# STM32U535 register map
File version: 1.7
CPU: CM33 r0p1, little endian, MPU, FPU, 4 interrupt priority bits
Registers are 32-bit, read-write, reset 0x0 unless marked. A register's access mark holds for its fields unless they carry their own. Offsets are from the block's base; [hi:lo] are bit positions; lines under a group give offsets from that group; {n}, {i} and the like mark numbered series; 'fields as' and 'values as' point back to an identical list.

## TAMP — Tamper and backup registers
Base 0x46007C00
Same registers: SEC_TAMP 0x56007C00
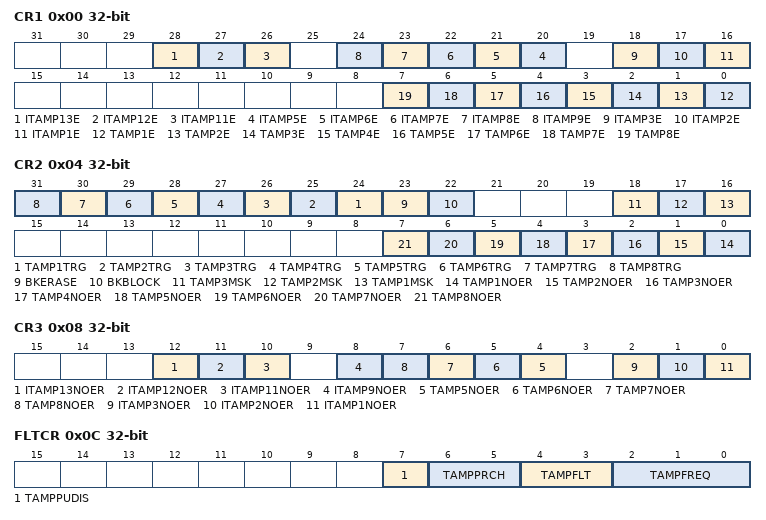
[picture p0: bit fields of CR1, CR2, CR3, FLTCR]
0x00 CR1 — control register 1
  [28] ITAMP13E
  [27] ITAMP12E
  [26] ITAMP11E — TAMP1E
  [n+15] ITAMP{n}E (n=5..9)
  [18] ITAMP3E
  [17] ITAMP2E
  [16] ITAMP1E
  [n-1] TAMP{n}E (n=1..8)
0x04 CR2 — control register 2
  [n+23] TAMP{n}TRG (n=1..8), [23] BKERASE, [22] BKBLOCK, [18] TAMP3MSK, [17] TAMP2MSK, [16] TAMP1MSK, [n-1] TAMP{n}NOER (n=1..8)
0x08 CR3 — control register 3
  [12] ITAMP13NOER, [11] ITAMP12NOER, [10] ITAMP11NOER, [8] ITAMP9NOER, [n-1] TAMP{n}NOER (n=5..8), [2] ITAMP3NOER, [1] ITAMP2NOER, [0] ITAMP1NOER
0x0C FLTCR — TAMP filter control register
  [7] TAMPPUDIS, [6:5] TAMPPRCH, [4:3] TAMPFLT, [2:0] TAMPFREQ
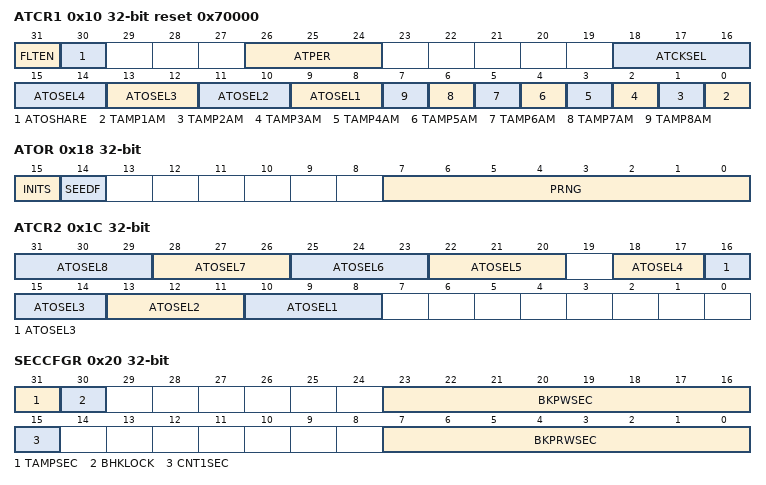
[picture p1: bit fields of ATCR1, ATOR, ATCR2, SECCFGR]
0x10 ATCR1 reset 0x70000 — TAMP active tamper control register
  [31] FLTEN — ATOSHARE
  [30] ATOSHARE
  [26:24] ATPER
  [18:16] ATCKSEL
  [2n+7:2n+6] ATOSEL{n} (n=1..4)
  [n-1] TAMP{n}AM (n=1..8)
0x14 ATSEEDR — TAMP active tamper seed register
  [31:0] SEED
0x18 ATOR ro — TAMP active tamper output register
  [15] INITS, [14] SEEDF, [7:0] PRNG
0x1C ATCR2 — TAMP active tamper control register 2
  [3n+7:3n+5] ATOSEL{n} (n=5..8), [18:17] ATOSEL4, [16:14] ATOSEL3, [13:11] ATOSEL2, [10:8] ATOSEL1
0x20 SECCFGR — TAMP secure mode register
  [31] TAMPSEC, [30] BHKLOCK, [23:16] BKPWSEC, [15] CNT1SEC, [7:0] BKPRWSEC
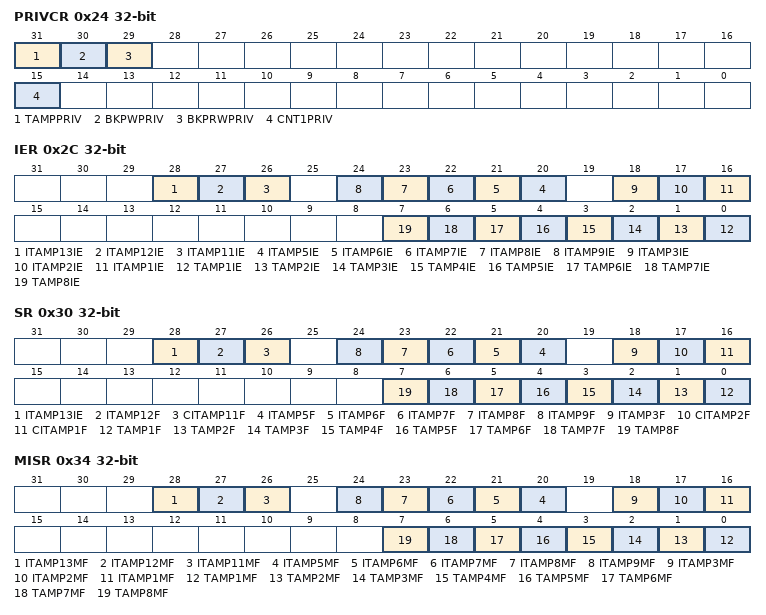
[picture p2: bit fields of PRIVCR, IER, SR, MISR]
0x24 PRIVCR — TAMP privilege mode control register
  [31] TAMPPRIV, [30] BKPWPRIV, [29] BKPRWPRIV, [15] CNT1PRIV
0x2C IER — TAMP interrupt enable register
  [28] ITAMP13IE, [27] ITAMP12IE, [26] ITAMP11IE, [n+15] ITAMP{n}IE (n=5..9), [18] ITAMP3IE, [17] ITAMP2IE, [16] ITAMP1IE, [n-1] TAMP{n}IE (n=1..8)
0x30 SR ro — TAMP status register
  [28] ITAMP13IE, [27] ITAMP12F, [26] CITAMP11F, [n+15] ITAMP{n}F (n=5..9), [18] ITAMP3F, [17] CITAMP2F, [16] CITAMP1F, [n-1] TAMP{n}F (n=1..8)
0x34 MISR ro — TAMP masked interrupt status register
  [28] ITAMP13MF, [27] ITAMP12MF, [26] ITAMP11MF, [n+15] ITAMP{n}MF (n=5..9), [18] ITAMP3MF, [17] ITAMP2MF, [16] ITAMP1MF, [n-1] TAMP{n}MF (n=1..8)
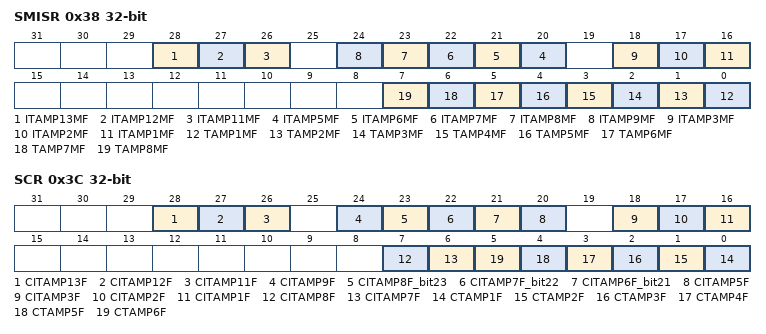
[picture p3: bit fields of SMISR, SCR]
0x38 SMISR ro — TAMP secure masked interrupt status register
  fields as MISR
0x3C SCR — TAMP status clear register
  [28] CITAMP13F
  [27] CITAMP12F
  [26] CITAMP11F
  [24] CITAMP9F
  [23] CITAMP8F_bit23
  [22] CITAMP7F_bit22
  [21] CITAMP6F_bit21
  [20] CITAMP5F
  [18] CITAMP3F
  [17] CITAMP2F
  [16] CITAMP1F
  [7] CITAMP8F — CITAMP3F
  [6] CITAMP7F — CITAMP3F
  [n-1] CTAMP{n}F (n=1..6)
0x40 COUNT1R ro — TAMP monotonic counter 1register
  [31:0] COUNT
0x54 ERCFGR — TAMP erase configuration register
  [0] ERCFG0
{0x100+4i} BKP{i}R (i=0..31) — TAMP backup register
  [31:0] BKP

## TIM6 — General-purpose-timers
Base 0x40001000
Same registers: TIM7 0x40001400, SEC_TIM6 0x50001000, SEC_TIM7 0x50001400
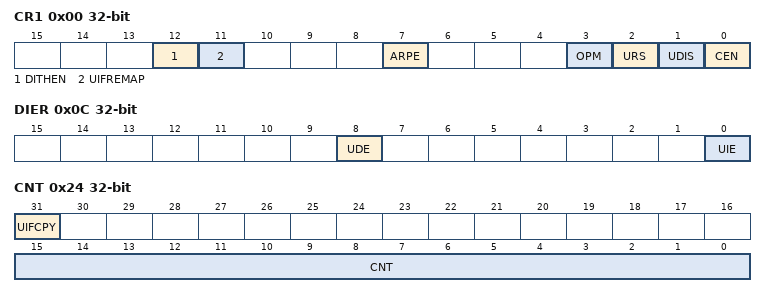
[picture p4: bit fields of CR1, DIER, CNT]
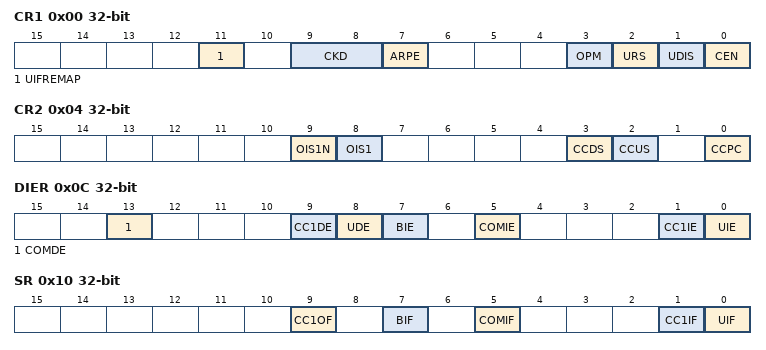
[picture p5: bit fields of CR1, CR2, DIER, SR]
0x00 CR1 — control register 1
  [12] DITHEN — Dithering Enable
  [11] UIFREMAP — UIF status bit remapping
  [7] ARPE — Auto-reload preload enable
  [3] OPM — One-pulse mode
  [2] URS — Update request source
  [1] UDIS — Update disable
  [0] CEN — Counter enable
0x04 CR2 — control register 2
  [6:4] MMS — Master mode selection
0x0C DIER — DMA/Interrupt enable register
  [8] UDE, [0] UIE
0x10 SR — status register
  [0] UIF
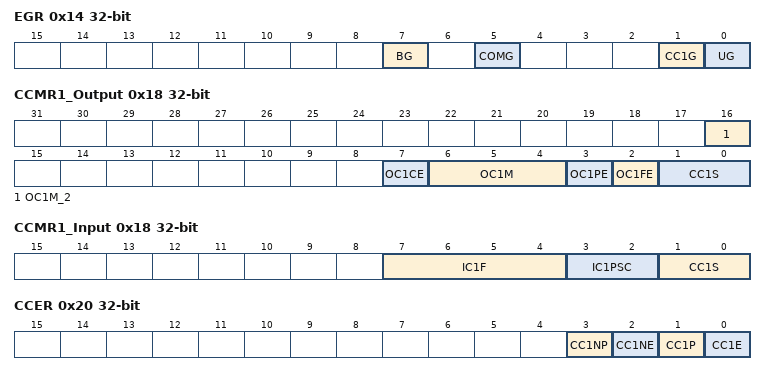
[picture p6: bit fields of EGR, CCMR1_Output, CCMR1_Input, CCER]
0x14 EGR wo — event generation register
  [0] UG
0x24 CNT — counter
  [31] UIFCPY, [15:0] CNT
0x28 PSC — prescaler
  [15:0] PSC
0x2C ARR reset 0xFFFF — auto-reload register
  [19:0] ARR

## TIM16 — General purpose timers
Base 0x40014400
Same registers: TIM17 0x40014800, SEC_TIM16 0x50014400, SEC_TIM17 0x50014800
0x00 CR1 — control register 1
  [11] UIFREMAP — UIF status bit remapping
  [9:8] CKD — Clock division
  [7] ARPE — Auto-reload preload enable
  [3] OPM — One pulse mode
  [2] URS — Update request source
  [1] UDIS — Update disable
  [0] CEN — Counter enable
0x04 CR2 — control register 2
  [9] OIS1N — Output Idle state 1
  [8] OIS1 — Output Idle state 1
  [3] CCDS — Capture/compare DMA
  [2] CCUS — Capture/compare control update
  [0] CCPC — Capture/compare preloaded
0x0C DIER — DMA/interrupt enable register
  [13] COMDE — COM DMA request enable
  [9] CC1DE — Capture/Compare 1 DMA request enable
  [8] UDE — Update DMA request enable
  [7] BIE — Break interrupt enable
  [5] COMIE — COM interrupt enable
  [1] CC1IE — Capture/Compare 1 interrupt enable
  [0] UIE — Update interrupt enable
0x10 SR — status register
  [9] CC1OF
  [7] BIF — Break interrupt flag
  [5] COMIF — COM interrupt flag
  [1] CC1IF — Capture/Compare 1 interrupt flag
  [0] UIF — Update interrupt flag
0x14 EGR wo — event generation register
  [7] BG — Break generation
  [5] COMG — Capture/Compare control update
  [1] CC1G — Capture/compare 1
  [0] UG — Update generation
0x18 CCMR1_Output — capture/compare mode register (output
  [16] OC1M_2 — Output Compare 1 mode
  [7] OC1CE — Output Compare 1 clear enable
  [6:4] OC1M — Output Compare 1 mode
  [3] OC1PE — Output Compare 1 preload
  [2] OC1FE — Output Compare 1 fast
  [1:0] CC1S — Capture/Compare 1
0x18 CCMR1_Input (alternate view of CCMR1_Output) — capture/compare mode register 1 (input
  [7:4] IC1F — Input capture 1 filter
  [3:2] IC1PSC — Input capture 1 prescaler
  [1:0] CC1S — Capture/Compare 1
0x20 CCER — capture/compare enable
  [3] CC1NP — Capture/Compare 1 output
  [2] CC1NE — Capture/Compare 1 complementary output
  [1] CC1P — Capture/Compare 1 output
  [0] CC1E — Capture/Compare 1 output
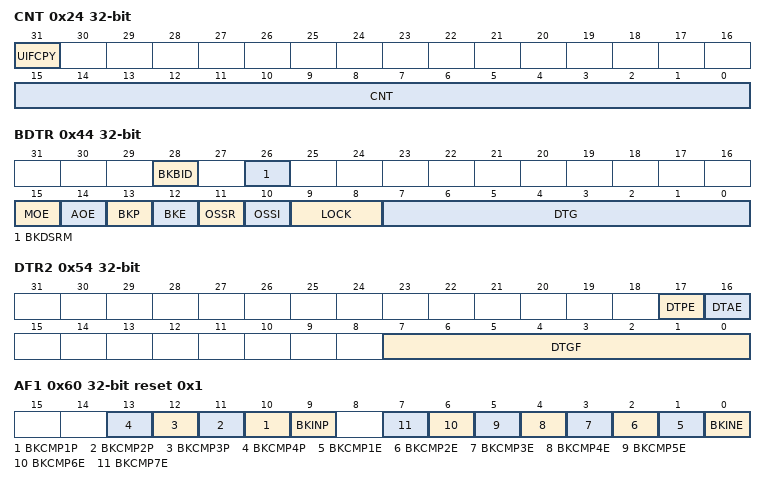
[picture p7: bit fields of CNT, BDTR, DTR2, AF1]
0x24 CNT access per field — counter
  [31] UIFCPY ro — UIF Copy
  [15:0] CNT rw
0x28 PSC — prescaler
  [15:0] PSC — Prescaler value
0x2C ARR reset 0xFFFF — auto-reload register
  [19:0] ARR — Auto-reload value
0x30 RCR — repetition counter register
  [7:0] REP — Repetition counter value
0x34 CCR1 — capture/compare register 1
  [19:0] CCR1 — Capture/Compare 1 value
0x44 BDTR — break and dead-time register
  [28] BKBID — Break Bidirectional
  [26] BKDSRM — Break Disarm
  [15] MOE — Main output enable
  [14] AOE — Automatic output enable
  [13] BKP — Break polarity
  [12] BKE — Break enable
  [11] OSSR — Off-state selection for Run
  [10] OSSI — Off-state selection for Idle
  [9:8] LOCK — Lock configuration
  [7:0] DTG — Dead-time generator setup
0x54 DTR2 — timer deadtime register 2
  [17] DTPE — Deadtime preload enable
  [16] DTAE — Deadtime asymmetric enable
  [7:0] DTGF — Deadtime asymmetric enable
0x5C TISEL — TIM17 option register 1
  [3:0] TI1SEL — selects tim_ti1_in[0..15] input
0x60 AF1 reset 0x1 — alternate function register 1
  [n+9] BKCMP{n}P (n=1..4) — tim_brk_cmp{n} input polarity
  [9] BKINP — TIMx_BKIN input polarity
  [n] BKCMP{n}E (n=1..7) — tim_brk_cmp{n} enable
  [0] BKINE — TIMx_BKIN input enable
0x64 AF2 reset 0x1 — alternate function register 2
  [18:16] OCRSEL — tim_ocref_clr source selection
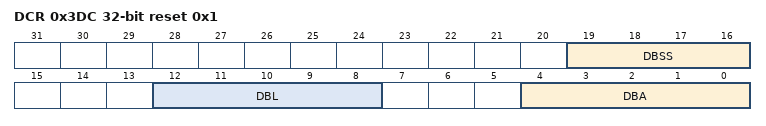
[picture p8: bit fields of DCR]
0x3DC DCR reset 0x1 — DMA control register
  [19:16] DBSS — DMA burst source selection
  [12:8] DBL — DMA burst length
  [4:0] DBA — DMA base address
0x3E0 DMAR reset 0x1 — TIM17 option register 1
  [31:0] DMAB — DMA register for burst accesses

## TSC — Touch sensing controller
Base 0x40024000
Same registers: SEC_TSC 0x50024000
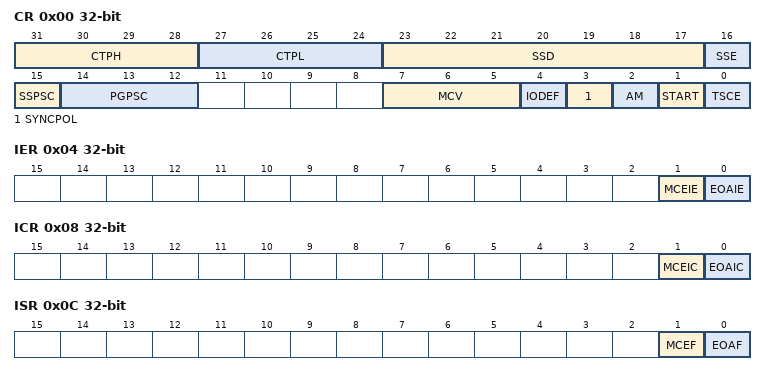
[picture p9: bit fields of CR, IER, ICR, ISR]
0x00 CR — control register
  [31:28] CTPH — Charge transfer pulse high
  [27:24] CTPL — Charge transfer pulse low
  [23:17] SSD — Spread spectrum deviation
  [16] SSE — Spread spectrum enable
  [15] SSPSC — Spread spectrum prescaler
  [14:12] PGPSC — pulse generator prescaler
  [7:5] MCV — Max count value
  [4] IODEF — I/O Default mode
  [3] SYNCPOL — Synchronization pin
  [2] AM — Acquisition mode
  [1] START — Start a new acquisition
  [0] TSCE — Touch sensing controller
0x04 IER — interrupt enable register
  [1] MCEIE — Max count error interrupt
  [0] EOAIE — End of acquisition interrupt
0x08 ICR — interrupt clear register
  [1] MCEIC — Max count error interrupt
  [0] EOAIC — End of acquisition interrupt
0x0C ISR ro — interrupt status register
  [1] MCEF — Max count error flag
  [0] EOAF — End of acquisition flag
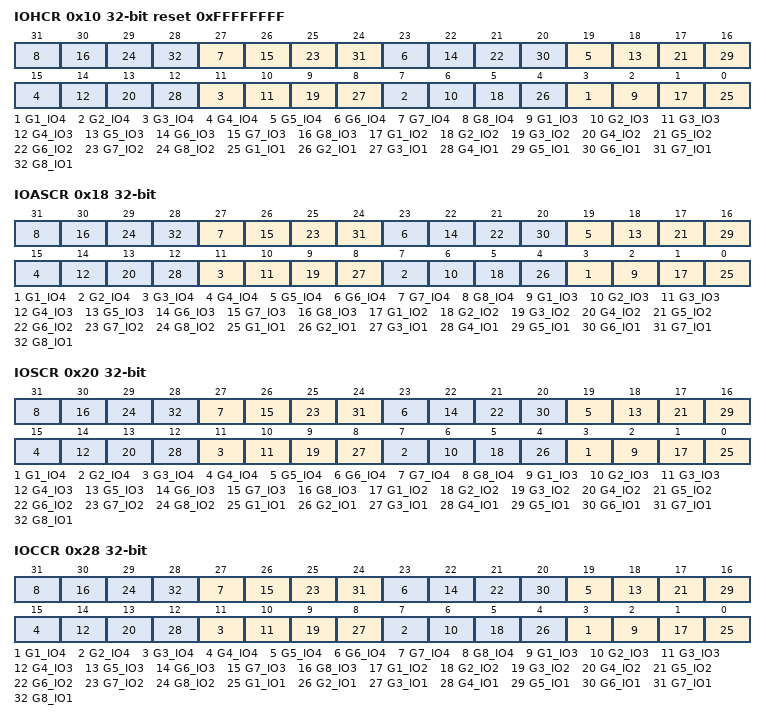
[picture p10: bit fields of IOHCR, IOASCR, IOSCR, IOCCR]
0x10 IOHCR reset 0xFFFFFFFF — I/O hysteresis control
  [4n-1] G{n}_IO4 (n=1..8), [4n-2] G{n}_IO3 (n=1..8), [4n-3] G{n}_IO2 (n=1..8), [4n-4] G{n}_IO1 (n=1..8)
0x18 IOASCR — I/O analog switch control
  fields as IOHCR
0x20 IOSCR — I/O sampling control register
  fields as IOHCR
0x28 IOCCR — I/O channel control register
  fields as IOHCR
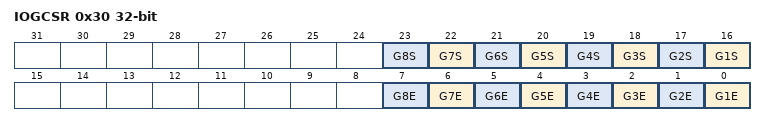
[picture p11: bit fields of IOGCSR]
0x30 IOGCSR access per field — I/O group control status
  [n+15] G{n}S ro (n=1..8) — Analog I/O group x status
  [n-1] G{n}E rw (n=1..8) — Analog I/O group x enable
{0x30+4i} IOG{i}CR ro (i=1..8) — I/O group x counter register
  [13:0] CNT — Counter value

## VREFBUF — Voltage reference buffer
Base 0x46007400
Same registers: SEC_VREFBUF 0x56007400
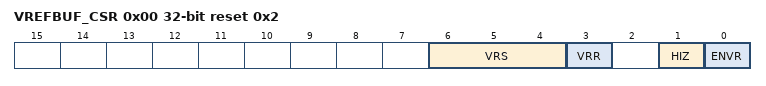
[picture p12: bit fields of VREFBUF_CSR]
0x00 VREFBUF_CSR access per field reset 0x2 — VREFBUF control and status register
  [6:4] VRS rw, [3] VRR ro, [1] HIZ rw, [0] ENVR rw
0x04 VREFBUF_CCR — VREFBUF calibration control register
  [5:0] TRIM

## WWDG — System window watchdog
Base 0x40002C00
Same registers: SEC_WWDG 0x50002C00
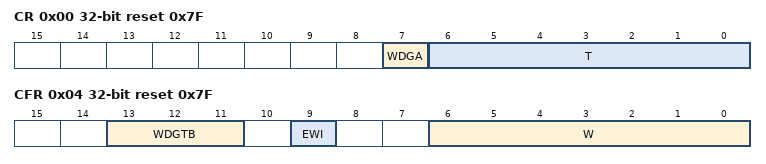
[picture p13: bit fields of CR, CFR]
0x00 CR reset 0x7F — Control register
  [7] WDGA — Activation bit
  [6:0] T — 7-bit counter (MSB to LSB)
0x04 CFR reset 0x7F — Configuration register
  [13:11] WDGTB — Timer base
  [9] EWI — Early wakeup interrupt
  [6:0] W — 7-bit window value
0x08 SR — Status register
  [0] EWIF — Early wakeup interrupt

## DCB — Debug Control Block
Base 0xE000EE08
0x00 DSCSR — Debug Security Control and Status Register
  [16] CDS — Current domain Secure
